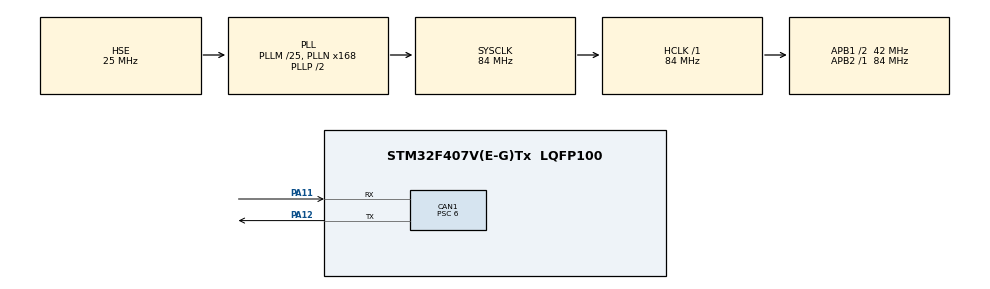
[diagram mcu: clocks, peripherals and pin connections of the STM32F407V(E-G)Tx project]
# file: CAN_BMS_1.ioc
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CAN1.ABOM=ENABLE
CAN1.AWUM=ENABLE
CAN1.BS1=CAN_BS1_11TQ
CAN1.BS2=CAN_BS2_2TQ
CAN1.CalculateBaudRate=500000
CAN1.CalculateTimeBit=2000
CAN1.CalculateTimeQuantum=142.85714285714286
CAN1.NART=ENABLE
CAN1.Prescaler=6
Mcu.Family=STM32F4
Mcu.Name=STM32F407V(E-G)Tx
Mcu.Package=LQFP100
NVIC.CAN1_RX0_IRQn=true\:0\:0\:false\:false\:true\:true\:true\:true
NVIC.CAN1_RX1_IRQn=true\:0\:0\:false\:false\:true\:true\:true\:true
NVIC.CAN1_SCE_IRQn=true\:0\:0\:false\:false\:true\:true\:true\:true
NVIC.CAN1_TX_IRQn=true\:0\:0\:false\:false\:true\:true\:true\:true
NVIC.PriorityGroup=NVIC_PRIORITYGROUP_4
NVIC.TIM2_IRQn=true\:0\:0\:false\:false\:true\:true\:true\:true
PA11.Mode=CAN_Activate
PA11.Signal=CAN1_RX
PA12.Mode=CAN_Activate
PA12.Signal=CAN1_TX
PH0-OSC_IN.Mode=HSE-External-Oscillator
PH0-OSC_IN.Signal=RCC_OSC_IN
PH1-OSC_OUT.Mode=HSE-External-Oscillator
PH1-OSC_OUT.Signal=RCC_OSC_OUT
ProjectManager.HeapSize=0x200
ProjectManager.StackSize=0x400
ProjectManager.TargetToolchain=STM32CubeIDE
RCC.48MHZClocksFreq_Value=42000000
RCC.AHBFreq_Value=84000000
RCC.APB1CLKDivider=RCC_HCLK_DIV2
RCC.APB1Freq_Value=42000000
RCC.APB1TimFreq_Value=84000000
RCC.APB2Freq_Value=84000000
RCC.APB2TimFreq_Value=84000000
RCC.CortexFreq_Value=84000000
RCC.HCLKFreq_Value=84000000
RCC.HSE_VALUE=25000000
RCC.HSI_VALUE=16000000
RCC.LSE_VALUE=32768
RCC.PLLM=25
RCC.PLLN=168
RCC.PLLSourceVirtual=RCC_PLLSOURCE_HSE
RCC.SYSCLKFreq_VALUE=84000000
RCC.SYSCLKSource=RCC_SYSCLKSOURCE_PLLCLK
RCC.VCOOutputFreq_Value=168000000
TIM2.AutoReloadPreload=TIM_AUTORELOAD_PRELOAD_ENABLE
TIM2.Period=999
TIM2.Prescaler=83
TIM5.AutoReloadPreload=TIM_AUTORELOAD_PRELOAD_ENABLE
TIM5.Period=0xffffffff
TIM5.Prescaler=83
VP_TIM2_VS_ClockSourceINT.Mode=Internal
VP_TIM5_VS_ClockSourceINT.Mode=Internal
board=custom

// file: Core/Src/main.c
/* USER CODE BEGIN Header */
/**
 ******************************************************************************
 * @file           : main.c
 * @brief          : Main program body
 ******************************************************************************
 * @attention
 *
 * Copyright (c) 2025 STMicroelectronics.
 * All rights reserved.
 *
 * This software is licensed under terms that can be found in the LICENSE file
 * in the root directory of this software component.
 * If no LICENSE file comes with this software, it is provided AS-IS.
 *
 ******************************************************************************
 */
/* USER CODE END Header */
#include "main.h"

/* USER CODE BEGIN Includes */
#include "can_queue.h"
#include "can_process.h"
#include "timer.h"
#include "bms_data.h"
/* USER CODE END Includes */

CAN_HandleTypeDef hcan1;

TIM_HandleTypeDef htim2;
TIM_HandleTypeDef htim5;

void SystemClock_Config(void);
static void MX_GPIO_Init(void);
static void MX_CAN1_Init(void);
static void MX_TIM2_Init(void);
static void MX_TIM5_Init(void);

int main(void)
{

	/* MCU Configuration--------------------------------------------------------*/

	/* Reset of all peripherals, Initializes the Flash interface and the Systick. */
	HAL_Init();

	/* Configure the system clock */
	SystemClock_Config();

	/* Initialize all configured peripherals */
	MX_GPIO_Init();
	MX_CAN1_Init();
	MX_TIM2_Init();
	MX_TIM5_Init();
	timers_start();
	canq_init();
	bms_table_init();

	/* Infinite loop */
	/* USER CODE BEGIN WHILE */
	while (1)
	{

		process_can_frames();

		/* USER CODE END WHILE */

	}
}

void SystemClock_Config(void)
{
	RCC_OscInitTypeDef RCC_OscInitStruct = {0};
	RCC_ClkInitTypeDef RCC_ClkInitStruct = {0};

	/** Configure the main internal regulator output voltage
	 */
	__HAL_RCC_PWR_CLK_ENABLE();
	__HAL_PWR_VOLTAGESCALING_CONFIG(PWR_REGULATOR_VOLTAGE_SCALE1);

	/** Initializes the RCC Oscillators according to the specified parameters
	 * in the RCC_OscInitTypeDef structure.
	 */
	RCC_OscInitStruct.OscillatorType = RCC_OSCILLATORTYPE_HSE;
	RCC_OscInitStruct.HSEState = RCC_HSE_ON;
	RCC_OscInitStruct.PLL.PLLState = RCC_PLL_ON;
	RCC_OscInitStruct.PLL.PLLSource = RCC_PLLSOURCE_HSE;
	RCC_OscInitStruct.PLL.PLLM = 25;
	RCC_OscInitStruct.PLL.PLLN = 168;
	RCC_OscInitStruct.PLL.PLLP = RCC_PLLP_DIV2;
	RCC_OscInitStruct.PLL.PLLQ = 4;
	if (HAL_RCC_OscConfig(&RCC_OscInitStruct) != HAL_OK)
	{
		Error_Handler();
	}

	/** Initializes the CPU, AHB and APB buses clocks
	 */
	RCC_ClkInitStruct.ClockType = RCC_CLOCKTYPE_HCLK|RCC_CLOCKTYPE_SYSCLK
			|RCC_CLOCKTYPE_PCLK1|RCC_CLOCKTYPE_PCLK2;
	RCC_ClkInitStruct.SYSCLKSource = RCC_SYSCLKSOURCE_PLLCLK;
	RCC_ClkInitStruct.AHBCLKDivider = RCC_SYSCLK_DIV1;
	RCC_ClkInitStruct.APB1CLKDivider = RCC_HCLK_DIV2;
	RCC_ClkInitStruct.APB2CLKDivider = RCC_HCLK_DIV1;

	if (HAL_RCC_ClockConfig(&RCC_ClkInitStruct, FLASH_LATENCY_2) != HAL_OK)
	{
		Error_Handler();
	}
}

static void MX_CAN1_Init(void)
{

	hcan1.Instance = CAN1;
	hcan1.Init.Prescaler = 6;
	hcan1.Init.Mode = CAN_MODE_NORMAL;
	hcan1.Init.SyncJumpWidth = CAN_SJW_1TQ;
	hcan1.Init.TimeSeg1 = CAN_BS1_11TQ;
	hcan1.Init.TimeSeg2 = CAN_BS2_2TQ;
	hcan1.Init.TimeTriggeredMode = DISABLE;
	hcan1.Init.AutoBusOff = ENABLE;
	hcan1.Init.AutoWakeUp = ENABLE;
	hcan1.Init.AutoRetransmission = ENABLE;
	hcan1.Init.ReceiveFifoLocked = DISABLE;
	hcan1.Init.TransmitFifoPriority = DISABLE;
	if (HAL_CAN_Init(&hcan1) != HAL_OK)
	{
		Error_Handler();
	}
	/* USER CODE BEGIN CAN1_Init 2 */

	CAN_FilterTypeDef sFilterConfig;

	sFilterConfig.FilterBank = 0;                        // use filter bank 0
	sFilterConfig.FilterMode = CAN_FILTERMODE_IDMASK;    // mask mode
	sFilterConfig.FilterScale = CAN_FILTERSCALE_32BIT;   // 32-bit scale (single filter)
	sFilterConfig.FilterFIFOAssignment = CAN_FILTER_FIFO0;
	sFilterConfig.FilterActivation = ENABLE;

	// Accept everything: ID = 0, Mask = 0
	sFilterConfig.FilterIdHigh = 0x0000;
	sFilterConfig.FilterIdLow  = 0x0000;
	sFilterConfig.FilterMaskIdHigh = 0x0000;
	sFilterConfig.FilterMaskIdLow  = 0x0000;

	if (HAL_CAN_ConfigFilter(&hcan1, &sFilterConfig) != HAL_OK) {
		Error_Handler();
	}

	if (HAL_CAN_Start(&hcan1) != HAL_OK) { Error_Handler(); }
	if (HAL_CAN_ActivateNotification(&hcan1, CAN_IT_RX_FIFO0_MSG_PENDING) != HAL_OK) { Error_Handler(); }

	/* USER CODE END CAN1_Init 2 */

}

static void MX_TIM2_Init(void)
{

	TIM_ClockConfigTypeDef sClockSourceConfig = {0};
	TIM_MasterConfigTypeDef sMasterConfig = {0};

	htim2.Instance = TIM2;
	htim2.Init.Prescaler = 83;
	htim2.Init.CounterMode = TIM_COUNTERMODE_UP;
	htim2.Init.Period = 999;
	htim2.Init.ClockDivision = TIM_CLOCKDIVISION_DIV1;
	htim2.Init.AutoReloadPreload = TIM_AUTORELOAD_PRELOAD_ENABLE;
	if (HAL_TIM_Base_Init(&htim2) != HAL_OK)
	{
		Error_Handler();
	}
	sClockSourceConfig.ClockSource = TIM_CLOCKSOURCE_INTERNAL;
	if (HAL_TIM_ConfigClockSource(&htim2, &sClockSourceConfig) != HAL_OK)
	{
		Error_Handler();
	}
	sMasterConfig.MasterOutputTrigger = TIM_TRGO_RESET;
	sMasterConfig.MasterSlaveMode = TIM_MASTERSLAVEMODE_DISABLE;
	if (HAL_TIMEx_MasterConfigSynchronization(&htim2, &sMasterConfig) != HAL_OK)
	{
		Error_Handler();
	}

}

static void MX_TIM5_Init(void)
{

	TIM_ClockConfigTypeDef sClockSourceConfig = {0};
	TIM_MasterConfigTypeDef sMasterConfig = {0};

	htim5.Instance = TIM5;
	htim5.Init.Prescaler = 83;
	htim5.Init.CounterMode = TIM_COUNTERMODE_UP;
	htim5.Init.Period = 0xffffffff;
	htim5.Init.ClockDivision = TIM_CLOCKDIVISION_DIV1;
	htim5.Init.AutoReloadPreload = TIM_AUTORELOAD_PRELOAD_ENABLE;
	if (HAL_TIM_Base_Init(&htim5) != HAL_OK)
	{
		Error_Handler();
	}
	sClockSourceConfig.ClockSource = TIM_CLOCKSOURCE_INTERNAL;
	if (HAL_TIM_ConfigClockSource(&htim5, &sClockSourceConfig) != HAL_OK)
	{
		Error_Handler();
	}
	sMasterConfig.MasterOutputTrigger = TIM_TRGO_RESET;
	sMasterConfig.MasterSlaveMode = TIM_MASTERSLAVEMODE_DISABLE;
	if (HAL_TIMEx_MasterConfigSynchronization(&htim5, &sMasterConfig) != HAL_OK)
	{
		Error_Handler();
	}

}

static void MX_GPIO_Init(void)
{

	/* GPIO Ports Clock Enable */
	__HAL_RCC_GPIOH_CLK_ENABLE();
	__HAL_RCC_GPIOA_CLK_ENABLE();

}

void Error_Handler(void)
{
	__disable_irq();
	while (1)
	{
	}
}
